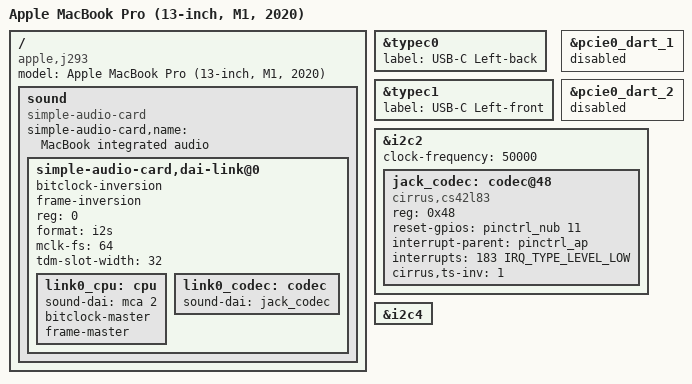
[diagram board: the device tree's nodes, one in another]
// SPDX-License-Identifier: GPL-2.0+ OR MIT
/*
 * Apple MacBook Pro (13-inch, M1, 2020)
 *
 * target-type: J293
 *
 * Copyright The Asahi Linux Contributors
 */

/dts-v1/;

#include "t8103.dtsi"
#include "t8103-jxxx.dtsi"

/ {
	compatible = "apple,j293", "apple,t8103", "apple,arm-platform";
	model = "Apple MacBook Pro (13-inch, M1, 2020)";
};

/*
 * Provide labels for the USB type C ports.
 */

&typec0 {
	label = "USB-C Left-back";
};

&typec1 {
	label = "USB-C Left-front";
};

/*
 * Remove unused PCIe ports and disable the associated DARTs.
 */

&pcie0_dart_1 {
	status = "disabled";
};

&pcie0_dart_2 {
	status = "disabled";
};

/delete-node/ &port01;
/delete-node/ &port02;

&i2c2 {
	status = "okay";
	clock-frequency = <50000>;

	jack_codec: codec@48 {
		compatible = "cirrus,cs42l83", "cirrus,cs42l42";
		reg = <0x48>;
		reset-gpios = <&pinctrl_nub 11 GPIO_ACTIVE_HIGH>;
		interrupt-parent = <&pinctrl_ap>;
		interrupts = <183 IRQ_TYPE_LEVEL_LOW>;
		#sound-dai-cells = <0>;
		cirrus,ts-inv = <1>;
	};
};

&i2c4 {
	status = "okay";
};

/ {
	sound {
		compatible = "simple-audio-card";
		simple-audio-card,name = "MacBook integrated audio";
		#address-cells = <1>;
		#size-cells = <0>;

		simple-audio-card,dai-link@0 {
			bitclock-inversion;
			frame-inversion;
			reg = <0>;
			format = "i2s";
			mclk-fs = <64>;
			tdm-slot-width = <32>;

			link0_cpu: cpu {
				sound-dai = <&mca 2>;
				bitclock-master;
				frame-master;
			};

			link0_codec: codec {
				sound-dai = <&jack_codec>;
			};
		};
	};
};
